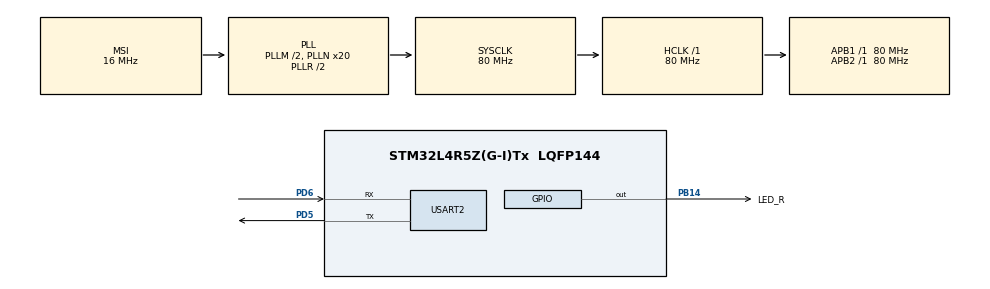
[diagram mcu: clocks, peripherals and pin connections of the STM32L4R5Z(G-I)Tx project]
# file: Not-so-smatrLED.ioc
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Dma.Request0=USART2_RX
Dma.USART2_RX.0.Direction=DMA_PERIPH_TO_MEMORY
Dma.USART2_RX.0.EventEnable=DISABLE
Dma.USART2_RX.0.Instance=DMA1_Channel1
Dma.USART2_RX.0.MemDataAlignment=DMA_MDATAALIGN_BYTE
Dma.USART2_RX.0.MemInc=DMA_MINC_ENABLE
Dma.USART2_RX.0.Mode=DMA_CIRCULAR
Dma.USART2_RX.0.PeriphDataAlignment=DMA_PDATAALIGN_BYTE
Dma.USART2_RX.0.PeriphInc=DMA_PINC_DISABLE
Dma.USART2_RX.0.Polarity=HAL_DMAMUX_REQUEST_GEN_RISING
Dma.USART2_RX.0.Priority=DMA_PRIORITY_MEDIUM
Dma.USART2_RX.0.RequestNumber=1
Dma.USART2_RX.0.SignalID=NONE
Dma.USART2_RX.0.SyncEnable=DISABLE
Dma.USART2_RX.0.SyncPolarity=HAL_DMAMUX_SYNC_NO_EVENT
Dma.USART2_RX.0.SyncRequestNumber=1
Dma.USART2_RX.0.SyncSignalID=NONE
Mcu.Family=STM32L4
Mcu.Name=STM32L4R5Z(G-I)Tx
Mcu.Package=LQFP144
NVIC.DMA1_Channel1_IRQn=true\:0\:0\:false\:false\:true\:false\:true\:true
NVIC.PriorityGroup=NVIC_PRIORITYGROUP_4
NVIC.RCC_IRQn=true\:0\:0\:false\:false\:true\:true\:false\:true
NVIC.TIM1_BRK_TIM15_IRQn=true\:0\:0\:false\:false\:true\:true\:true\:true
NVIC.TIM1_CC_IRQn=true\:0\:0\:false\:false\:true\:true\:true\:true
NVIC.TIM1_TRG_COM_TIM17_IRQn=true\:0\:0\:false\:false\:true\:true\:true\:true
NVIC.TIM1_UP_TIM16_IRQn=true\:0\:0\:false\:false\:true\:true\:true\:true
NVIC.USART2_IRQn=true\:0\:0\:false\:false\:true\:true\:true\:true
PA13\ (JTMS/SWDIO).Mode=Serial_Wire
PA13\ (JTMS/SWDIO).Signal=SYS_JTMS-SWDIO
PA14\ (JTCK/SWCLK).Mode=Serial_Wire
PA14\ (JTCK/SWCLK).Signal=SYS_JTCK-SWCLK
PB14.GPIO_Label=LED_R
PB14.GPIO_PuPd=GPIO_NOPULL
PB14.Signal=GPIO_Output
PC14-OSC32_IN\ (PC14).Mode=LSE-External-Oscillator
PC14-OSC32_IN\ (PC14).Signal=RCC_OSC32_IN
PC15-OSC32_OUT\ (PC15).Mode=LSE-External-Oscillator
PC15-OSC32_OUT\ (PC15).Signal=RCC_OSC32_OUT
PD5.Mode=Asynchronous
PD5.Signal=USART2_TX
PD6.Mode=Asynchronous
PD6.Signal=USART2_RX
ProjectManager.HeapSize=0x200
ProjectManager.StackSize=0x400
ProjectManager.TargetToolchain=STM32CubeIDE
RCC.ADCFreq_Value=64000000
RCC.AHBFreq_Value=80000000
RCC.APB1Freq_Value=80000000
RCC.APB1TimFreq_Value=80000000
RCC.APB2Freq_Value=80000000
RCC.APB2TimFreq_Value=80000000
RCC.CortexFreq_Value=80000000
RCC.HCLKFreq_Value=80000000
RCC.HSE_VALUE=8000000
RCC.HSI48_VALUE=48000000
RCC.HSI_VALUE=16000000
RCC.MSIClockRange=RCC_MSIRANGE_8
RCC.MSI_VALUE=16000000
RCC.PLLM1=2
RCC.PLLN=20
RCC.SYSCLKFreq_VALUE=80000000
RCC.SYSCLKSource=RCC_SYSCLKSOURCE_PLLCLK
RCC.USBFreq_Value=64000000
RCC.VCOOutputFreq_Value=160000000
TIM1.AutoReloadPreload=TIM_AUTORELOAD_PRELOAD_ENABLE
TIM1.Period=8000
TIM1.Prescaler=10000-1
USART2.VirtualMode-Asynchronous=VM_ASYNC
VP_TIM1_VS_ClockSourceINT.Mode=Internal
board=custom

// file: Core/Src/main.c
/* USER CODE BEGIN Header */
/**
  ******************************************************************************
  * @file           : main.c
  * @brief          : Main program body
  ******************************************************************************
  * @attention
  *
  * Copyright (c) 2023 STMicroelectronics.
  * All rights reserved.
  *
  * This software is licensed under terms that can be found in the LICENSE file
  * in the root directory of this software component.
  * If no LICENSE file comes with this software, it is provided AS-IS.
  *
  ******************************************************************************
  */
/* USER CODE END Header */
#include "main.h"
#include "dma.h"
#include "tim.h"
#include "usart.h"
#include "gpio.h"
#include "math.h"

/* USER CODE BEGIN PD */
uint8_t rx_buff[Rx_Size];
uint8_t test_buff[Rx_Size];
uint8_t data_len;
float pose_x, pose_y, pose_z;
float yaw, pitch;        //人相对相机
float tar_pitch, tar_yaw;     //人相对32
float offset_x, offset_y, offset_z;   //32相对相机，自定
float D;    //人与相机距离，自定
/* USER CODE END PD */

/* USER CODE BEGIN PM */
void HAL_TIM_PeriodElapsedCallback(TIM_HandleTypeDef *htim);
/* USER CODE END PM */

void SystemClock_Config(void);

int main(void)
{

  /* MCU Configuration--------------------------------------------------------*/

  /* Reset of all peripherals, Initializes the Flash interface and the Systick. */
  HAL_Init();

  /* Configure the system clock */
  SystemClock_Config();

  /* Initialize all configured peripherals */
  MX_GPIO_Init();
  MX_DMA_Init();
  MX_TIM1_Init();
  MX_USART2_UART_Init();
  /* USER CODE BEGIN 2 */
  HAL_TIM_Base_Start_IT(&htim1);
  HAL_UART_Receive_DMA(&huart2, rx_buff, Rx_Size);
  __HAL_UART_ENABLE_IT(&huart2, UART_IT_IDLE);
  /* USER CODE END 2 */

  /* Infinite loop */
  while (1)
  {

  }
}

void SystemClock_Config(void)
{
  RCC_OscInitTypeDef RCC_OscInitStruct = {0};
  RCC_ClkInitTypeDef RCC_ClkInitStruct = {0};

  /** Configure the main internal regulator output voltage
  */
  if (HAL_PWREx_ControlVoltageScaling(PWR_REGULATOR_VOLTAGE_SCALE1) != HAL_OK)
  {
    Error_Handler();
  }

  /** Initializes the RCC Oscillators according to the specified parameters
  * in the RCC_OscInitTypeDef structure.
  */
  RCC_OscInitStruct.OscillatorType = RCC_OSCILLATORTYPE_MSI;
  RCC_OscInitStruct.MSIState = RCC_MSI_ON;
  RCC_OscInitStruct.MSICalibrationValue = 0;
  RCC_OscInitStruct.MSIClockRange = RCC_MSIRANGE_8;
  RCC_OscInitStruct.PLL.PLLState = RCC_PLL_ON;
  RCC_OscInitStruct.PLL.PLLSource = RCC_PLLSOURCE_MSI;
  RCC_OscInitStruct.PLL.PLLM = 2;
  RCC_OscInitStruct.PLL.PLLN = 20;
  RCC_OscInitStruct.PLL.PLLP = RCC_PLLP_DIV2;
  RCC_OscInitStruct.PLL.PLLQ = RCC_PLLQ_DIV2;
  RCC_OscInitStruct.PLL.PLLR = RCC_PLLR_DIV2;
  if (HAL_RCC_OscConfig(&RCC_OscInitStruct) != HAL_OK)
  {
    Error_Handler();
  }

  /** Initializes the CPU, AHB and APB buses clocks
  */
  RCC_ClkInitStruct.ClockType = RCC_CLOCKTYPE_HCLK|RCC_CLOCKTYPE_SYSCLK
                              |RCC_CLOCKTYPE_PCLK1|RCC_CLOCKTYPE_PCLK2;
  RCC_ClkInitStruct.SYSCLKSource = RCC_SYSCLKSOURCE_PLLCLK;
  RCC_ClkInitStruct.AHBCLKDivider = RCC_SYSCLK_DIV1;
  RCC_ClkInitStruct.APB1CLKDivider = RCC_HCLK_DIV1;
  RCC_ClkInitStruct.APB2CLKDivider = RCC_HCLK_DIV1;

  if (HAL_RCC_ClockConfig(&RCC_ClkInitStruct, FLASH_LATENCY_3) != HAL_OK)
  {
    Error_Handler();
  }
}

/* USER CODE BEGIN 4 */
void HAL_TIM_PeriodElapsedCallback(TIM_HandleTypeDef *htim)
{
	if(htim->Instance == TIM1)
	{
		HAL_GPIO_TogglePin(LED_R_GPIO_Port, LED_R_Pin);
	}

}
void get_solve(uint8_t *data)
{
	//origin data in buffer is in ASCLL
	memcpy(test_buff, data, Rx_Size);
	if(test_buff[0] != 49 || test_buff[1] != 54 || test_buff[2] != 53)
		return;
	test_buff[4] -= 48;
	test_buff[8] -= 48;
	test_buff[9] -= 48;
	test_buff[10] -= 48;
	test_buff[11] -= 48;
	float temp = test_buff[8]*(1000) + test_buff[9]*(100) + test_buff[10]*(10) + test_buff[11]*(1);

	switch(test_buff[4])
	{	case 1:
			pose_x = temp;
			yaw = atanf((5000-pose_x)/5000);
			tar_yaw = atanf((offset_y-tanf(yaw)*D)/(D+offset_x));
			break;
		case 2:
			pose_y = temp;
			pitch = atanf((5000-pose_y)/5000);
			tar_pitch = -atanf((offset_z-tanf(pitch)*D)/(D+offset_x));
			break;
		case 3:
			pose_z = temp;   //误差过大,禁用
			break;
		default:
			return;
			break;
	}

}
/* USER CODE END 4 */

void Error_Handler(void)
{
  __disable_irq();
  while (1)
  {
  }
}
